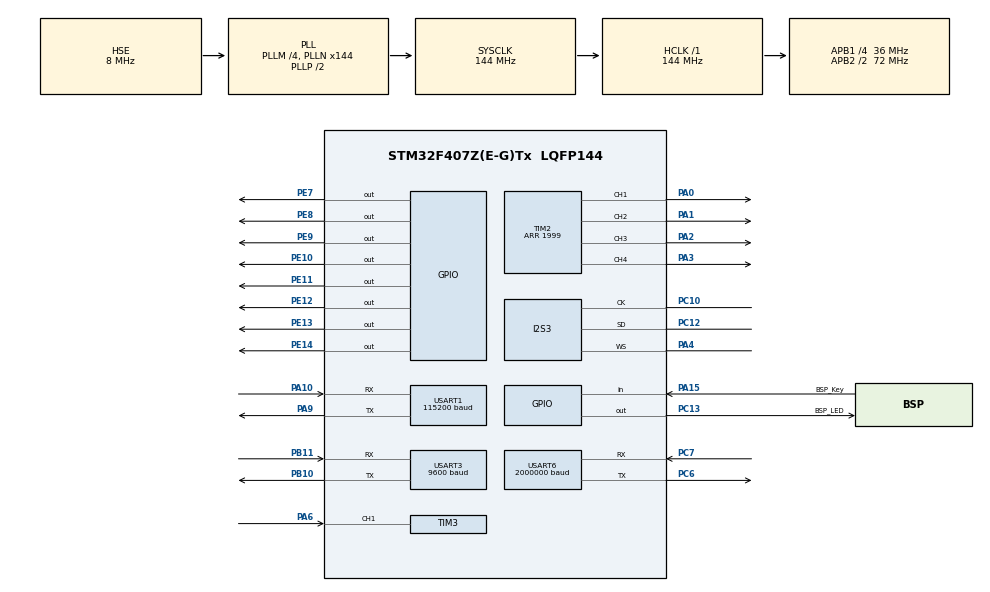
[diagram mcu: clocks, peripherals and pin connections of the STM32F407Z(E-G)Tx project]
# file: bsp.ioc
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Dma.Request0=USART6_RX
Dma.Request1=USART6_TX
Dma.Request2=SPI3_RX
Dma.SPI3_RX.2.Direction=DMA_PERIPH_TO_MEMORY
Dma.SPI3_RX.2.FIFOMode=DMA_FIFOMODE_DISABLE
Dma.SPI3_RX.2.Instance=DMA1_Stream0
Dma.SPI3_RX.2.MemDataAlignment=DMA_MDATAALIGN_HALFWORD
Dma.SPI3_RX.2.MemInc=DMA_MINC_ENABLE
Dma.SPI3_RX.2.Mode=DMA_NORMAL
Dma.SPI3_RX.2.PeriphDataAlignment=DMA_PDATAALIGN_HALFWORD
Dma.SPI3_RX.2.PeriphInc=DMA_PINC_DISABLE
Dma.SPI3_RX.2.Priority=DMA_PRIORITY_LOW
Dma.USART6_RX.0.Direction=DMA_PERIPH_TO_MEMORY
Dma.USART6_RX.0.FIFOMode=DMA_FIFOMODE_DISABLE
Dma.USART6_RX.0.Instance=DMA2_Stream1
Dma.USART6_RX.0.MemDataAlignment=DMA_MDATAALIGN_BYTE
Dma.USART6_RX.0.MemInc=DMA_MINC_ENABLE
Dma.USART6_RX.0.Mode=DMA_NORMAL
Dma.USART6_RX.0.PeriphDataAlignment=DMA_PDATAALIGN_BYTE
Dma.USART6_RX.0.PeriphInc=DMA_PINC_DISABLE
Dma.USART6_RX.0.Priority=DMA_PRIORITY_LOW
Dma.USART6_TX.1.Direction=DMA_MEMORY_TO_PERIPH
Dma.USART6_TX.1.FIFOMode=DMA_FIFOMODE_DISABLE
Dma.USART6_TX.1.Instance=DMA2_Stream6
Dma.USART6_TX.1.MemDataAlignment=DMA_MDATAALIGN_BYTE
Dma.USART6_TX.1.MemInc=DMA_MINC_ENABLE
Dma.USART6_TX.1.Mode=DMA_NORMAL
Dma.USART6_TX.1.PeriphDataAlignment=DMA_PDATAALIGN_BYTE
Dma.USART6_TX.1.PeriphInc=DMA_PINC_DISABLE
Dma.USART6_TX.1.Priority=DMA_PRIORITY_LOW
I2S3.AudioFreq=I2S_AUDIOFREQ_32K
I2S3.DataFormat=I2S_DATAFORMAT_24B
I2S3.ErrorAudioFreq=0.0 %
I2S3.FullDuplexMode=I2S_FULLDUPLEXMODE_DISABLE
I2S3.Instance=SPI$Index
I2S3.Mode=I2S_MODE_MASTER_RX
I2S3.RealAudioFreq=32.0 KHz
I2S3.Standard=I2S_STANDARD_MSB
I2S3.VirtualMode=I2S_MODE_MASTER
Mcu.Family=STM32F4
Mcu.Name=STM32F407Z(E-G)Tx
Mcu.Package=LQFP144
NVIC.DMA1_Stream0_IRQn=true\:0\:0\:false\:false\:true\:false\:true\:true
NVIC.DMA2_Stream1_IRQn=true\:0\:0\:false\:false\:true\:false\:true\:true
NVIC.DMA2_Stream6_IRQn=true\:0\:0\:false\:false\:true\:false\:true\:true
NVIC.PriorityGroup=NVIC_PRIORITYGROUP_4
NVIC.USART1_IRQn=true\:2\:0\:true\:false\:true\:true\:true\:true
NVIC.USART3_IRQn=true\:4\:0\:true\:false\:true\:true\:true\:true
NVIC.USART6_IRQn=true\:3\:0\:true\:false\:true\:true\:true\:true
PA0-WKUP.GPIO_ModeDefaultPP=GPIO_MODE_AF_OD
PA0-WKUP.Signal=S_TIM2_CH1_ETR
PA1.GPIO_ModeDefaultPP=GPIO_MODE_AF_OD
PA1.Signal=S_TIM2_CH2
PA10.Mode=Asynchronous
PA10.Signal=USART1_RX
PA13.Mode=Serial_Wire
PA13.Signal=SYS_JTMS-SWDIO
PA14.Mode=Serial_Wire
PA14.Signal=SYS_JTCK-SWCLK
PA15.GPIO_Label=BSP_Key
PA15.Signal=GPIO_Input
PA2.GPIO_ModeDefaultPP=GPIO_MODE_AF_OD
PA2.Signal=S_TIM2_CH3
PA3.GPIO_ModeDefaultPP=GPIO_MODE_AF_OD
PA3.Signal=S_TIM2_CH4
PA4.Mode=Half_Duplex_Master
PA4.Signal=I2S3_WS
PA6.Signal=S_TIM3_CH1
PA9.Mode=Asynchronous
PA9.Signal=USART1_TX
PB10.Mode=Asynchronous
PB10.Signal=USART3_TX
PB11.Mode=Asynchronous
PB11.Signal=USART3_RX
PC10.Mode=Half_Duplex_Master
PC10.Signal=I2S3_CK
PC12.Mode=Half_Duplex_Master
PC12.Signal=I2S3_SD
PC13-ANTI_TAMP.GPIO_Label=BSP_LED
PC13-ANTI_TAMP.GPIO_ModeDefaultOutputPP=GPIO_MODE_OUTPUT_OD
PC13-ANTI_TAMP.GPIO_PuPd=GPIO_PULLUP
PC13-ANTI_TAMP.Signal=GPIO_Output
PC6.Mode=Asynchronous
PC6.Signal=USART6_TX
PC7.Mode=Asynchronous
PC7.Signal=USART6_RX
PE10.Signal=GPIO_Output
PE11.Signal=GPIO_Output
PE12.Signal=GPIO_Output
PE13.Signal=GPIO_Output
PE14.Signal=GPIO_Output
PE7.Signal=GPIO_Output
PE8.Signal=GPIO_Output
PE9.Signal=GPIO_Output
PH0-OSC_IN.Mode=HSE-External-Oscillator
PH0-OSC_IN.Signal=RCC_OSC_IN
PH1-OSC_OUT.Mode=HSE-External-Oscillator
PH1-OSC_OUT.Signal=RCC_OSC_OUT
ProjectManager.HeapSize=0x300
ProjectManager.StackSize=0x400
ProjectManager.TargetToolchain=Makefile
RCC.48MHZClocksFreq_Value=72000000
RCC.AHBFreq_Value=144000000
RCC.APB1CLKDivider=RCC_HCLK_DIV4
RCC.APB1Freq_Value=36000000
RCC.APB1TimFreq_Value=72000000
RCC.APB2CLKDivider=RCC_HCLK_DIV2
RCC.APB2Freq_Value=72000000
RCC.APB2TimFreq_Value=144000000
RCC.CortexFreq_Value=144000000
RCC.HCLKFreq_Value=144000000
RCC.HSE_VALUE=8000000
RCC.HSI_VALUE=16000000
RCC.LSE_VALUE=32768
RCC.PLLI2SN=128
RCC.PLLI2SR=5
RCC.PLLM=4
RCC.PLLN=144
RCC.PLLSourceVirtual=RCC_PLLSOURCE_HSE
RCC.PWR_Regulator_Voltage_Scale=PWR_REGULATOR_VOLTAGE_SCALE2
RCC.SYSCLKFreq_VALUE=144000000
RCC.SYSCLKSource=RCC_SYSCLKSOURCE_PLLCLK
RCC.VCOOutputFreq_Value=288000000
SH.S_TIM2_CH1_ETR.0=TIM2_CH1,PWM Generation1 CH1
SH.S_TIM2_CH2.0=TIM2_CH2,PWM Generation2 CH2
SH.S_TIM2_CH3.0=TIM2_CH3,PWM Generation3 CH3
SH.S_TIM2_CH4.0=TIM2_CH4,PWM Generation4 CH4
SH.S_TIM3_CH1.0=TIM3_CH1,PWM_Input_1
TIM2.AutoReloadPreload=TIM_AUTORELOAD_PRELOAD_DISABLE
TIM2.Channel-PWM\ Generation1\ CH1=TIM_CHANNEL_1
TIM2.Channel-PWM\ Generation2\ CH2=TIM_CHANNEL_2
TIM2.Channel-PWM\ Generation3\ CH3=TIM_CHANNEL_3
TIM2.Channel-PWM\ Generation4\ CH4=TIM_CHANNEL_4
TIM2.Period=1999
TIM3.Prescaler=71
USART1.BaudRate=115200
USART1.VirtualMode=VM_ASYNC
USART3.BaudRate=9600
USART3.VirtualMode=VM_ASYNC
USART6.BaudRate=2000000
USART6.VirtualMode=VM_ASYNC
VP_TIM2_VS_ClockSourceINT.Mode=Internal
VP_TIM3_VS_ClockSourceINT.Mode=Internal
board=custom

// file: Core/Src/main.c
/* USER CODE BEGIN Header */
/**
  ******************************************************************************
  * @file           : main.c
  * @brief          : Main program body
  ******************************************************************************
  * @attention
  *
  * Copyright (c) 2025 STMicroelectronics.
  * All rights reserved.
  *
  * This software is licensed under terms that can be found in the LICENSE file
  * in the root directory of this software component.
  * If no LICENSE file comes with this software, it is provided AS-IS.
  *
  ******************************************************************************
  */
/* USER CODE END Header */
#include "main.h"
#include "dma.h"
#include "i2s.h"
#include "tim.h"
#include "usart.h"
#include "gpio.h"

/* USER CODE BEGIN Includes */

#include "user.h" // 引入用户头文件

/* USER CODE END Includes */

void SystemClock_Config(void);

int main(void)
{

  /* MCU Configuration--------------------------------------------------------*/

  /* Reset of all peripherals, Initializes the Flash interface and the Systick. */
  HAL_Init();

  /* Configure the system clock */
  SystemClock_Config();

  /* Initialize all configured peripherals */
  MX_GPIO_Init();
  MX_DMA_Init();
  MX_USART1_UART_Init();
  MX_TIM2_Init();
  MX_USART3_UART_Init();
  MX_USART6_UART_Init();
  MX_I2S3_Init();
  MX_TIM3_Init();
  /* USER CODE BEGIN 2 */

  user_init();

  /* USER CODE END 2 */

  /* Infinite loop */
  while (1)
  {

    /* USER CODE BEGIN 3 */

    user_deal();
  }
  /* USER CODE END 3 */
}

void SystemClock_Config(void)
{
  RCC_OscInitTypeDef RCC_OscInitStruct = {0};
  RCC_ClkInitTypeDef RCC_ClkInitStruct = {0};

  /** Configure the main internal regulator output voltage
  */
  __HAL_RCC_PWR_CLK_ENABLE();
  __HAL_PWR_VOLTAGESCALING_CONFIG(PWR_REGULATOR_VOLTAGE_SCALE2);

  /** Initializes the RCC Oscillators according to the specified parameters
  * in the RCC_OscInitTypeDef structure.
  */
  RCC_OscInitStruct.OscillatorType = RCC_OSCILLATORTYPE_HSE;
  RCC_OscInitStruct.HSEState = RCC_HSE_ON;
  RCC_OscInitStruct.PLL.PLLState = RCC_PLL_ON;
  RCC_OscInitStruct.PLL.PLLSource = RCC_PLLSOURCE_HSE;
  RCC_OscInitStruct.PLL.PLLM = 4;
  RCC_OscInitStruct.PLL.PLLN = 144;
  RCC_OscInitStruct.PLL.PLLP = RCC_PLLP_DIV2;
  RCC_OscInitStruct.PLL.PLLQ = 4;
  if (HAL_RCC_OscConfig(&RCC_OscInitStruct) != HAL_OK)
  {
    Error_Handler();
  }

  /** Initializes the CPU, AHB and APB buses clocks
  */
  RCC_ClkInitStruct.ClockType = RCC_CLOCKTYPE_HCLK|RCC_CLOCKTYPE_SYSCLK
                              |RCC_CLOCKTYPE_PCLK1|RCC_CLOCKTYPE_PCLK2;
  RCC_ClkInitStruct.SYSCLKSource = RCC_SYSCLKSOURCE_PLLCLK;
  RCC_ClkInitStruct.AHBCLKDivider = RCC_SYSCLK_DIV1;
  RCC_ClkInitStruct.APB1CLKDivider = RCC_HCLK_DIV4;
  RCC_ClkInitStruct.APB2CLKDivider = RCC_HCLK_DIV2;

  if (HAL_RCC_ClockConfig(&RCC_ClkInitStruct, FLASH_LATENCY_4) != HAL_OK)
  {
    Error_Handler();
  }
}

void Error_Handler(void)
{
  __disable_irq();
  while (1)
  {
  }
}
